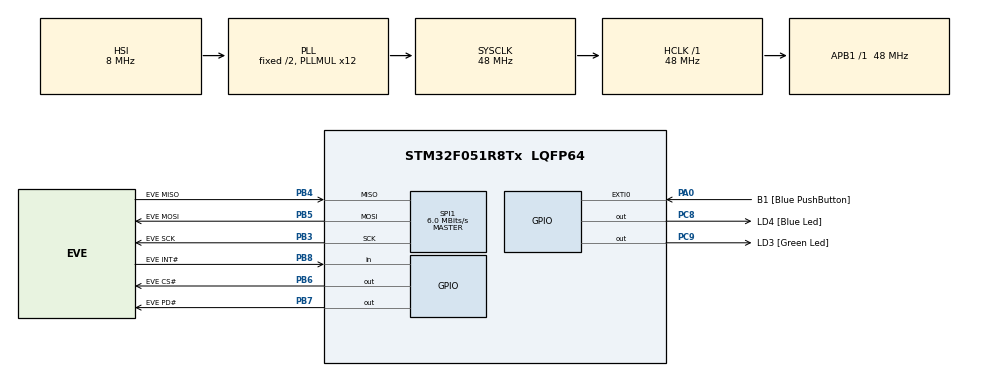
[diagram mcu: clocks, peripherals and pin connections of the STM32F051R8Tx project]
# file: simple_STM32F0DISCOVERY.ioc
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Mcu.Family=STM32F0
Mcu.Name=STM32F051R8Tx
Mcu.Package=LQFP64
PA0.GPIO_Label=B1 [Blue PushButton]
PA0.GPIO_ModeDefaultEXTI=GPIO_MODE_EVT_RISING
PA0.Signal=GPXTI0
PA13.GPIO_Label=SWDIO
PA13.Mode=Serial_Wire
PA13.Signal=SYS_SWDIO
PA14.GPIO_Label=SWCLK
PA14.Mode=Serial_Wire
PA14.Signal=SYS_SWCLK
PB3.GPIO_Label=EVE SCK
PB3.Mode=Full_Duplex_Master
PB3.Signal=SPI1_SCK
PB4.GPIO_Label=EVE MISO
PB4.Mode=Full_Duplex_Master
PB4.Signal=SPI1_MISO
PB5.GPIO_Label=EVE MOSI
PB5.Mode=Full_Duplex_Master
PB5.Signal=SPI1_MOSI
PB6.GPIO_Label=EVE CS\#
PB6.Signal=GPIO_Output
PB7.GPIO_Label=EVE PD\#
PB7.Signal=GPIO_Output
PB8.GPIO_Label=EVE INT\#
PB8.Signal=GPIO_Input
PC8.GPIO_Label=LD4 [Blue Led]
PC8.Signal=GPIO_Output
PC9.GPIO_Label=LD3 [Green Led]
PC9.Signal=GPIO_Output
ProjectManager.HeapSize=0x200
ProjectManager.StackSize=0x400
ProjectManager.TargetToolchain=STM32CubeIDE
RCC.AHBFreq_Value=48000000
RCC.APB1Freq_Value=48000000
RCC.APB1TimFreq_Value=48000000
RCC.HCLKFreq_Value=48000000
RCC.PLLMUL=RCC_PLL_MUL12
RCC.SYSCLKFreq_VALUE=48000000
RCC.SYSCLKSource=RCC_SYSCLKSOURCE_PLLCLK
SPI1.BaudRatePrescaler=SPI_BAUDRATEPRESCALER_8
SPI1.CalculateBaudRate=6.0 MBits/s
SPI1.DataSize=SPI_DATASIZE_8BIT
SPI1.Direction=SPI_DIRECTION_2LINES
SPI1.Mode=SPI_MODE_MASTER
SPI1.VirtualType=VM_MASTER
board=STM32F0DISCOVERY

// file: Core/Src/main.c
/* USER CODE BEGIN Header */
/**
  ******************************************************************************
  * @file           : main.c
  * @brief          : Main program body
  ******************************************************************************
  * @attention
  *
  * Copyright (c) 2026 STMicroelectronics.
  * All rights reserved.
  *
  * This software is licensed under terms that can be found in the LICENSE file
  * in the root directory of this software component.
  * If no LICENSE file comes with this software, it is provided AS-IS.
  *
  ******************************************************************************
  */
/* USER CODE END Header */
#include "main.h"

/* USER CODE BEGIN Includes */
#include <string.h>
#include <stdint.h> // for Uint8/16/32 and Int8/16/32 data types

/* Include the example interface and associated function prototypes. */
#include <eve_example.h>
/* USER CODE END Includes */

SPI_HandleTypeDef hspi1;

/* USER CODE BEGIN PV */

GPIO_TypeDef *config_gpio;
uint16_t config_pin_pd;
uint16_t config_pin_cs;
uint16_t config_pin_int;

/* USER CODE END PV */

void SystemClock_Config(void);
static void MX_GPIO_Init(void);
static void MX_SPI1_Init(void);

int main(void)
{

  /* MCU Configuration--------------------------------------------------------*/

  /* Reset of all peripherals, Initializes the Flash interface and the Systick. */
  HAL_Init();

  /* Configure the system clock */
  SystemClock_Config();

  /* Initialize all configured peripherals */
  MX_GPIO_Init();
  MX_SPI1_Init();
  /* USER CODE BEGIN 2 */

  /* Start example code */
  eve_example();

  /* USER CODE END 2 */

  /* Infinite loop */
  while (1)
  {

  }
}

void SystemClock_Config(void)
{
  RCC_OscInitTypeDef RCC_OscInitStruct = {0};
  RCC_ClkInitTypeDef RCC_ClkInitStruct = {0};

  /** Initializes the RCC Oscillators according to the specified parameters
  * in the RCC_OscInitTypeDef structure.
  */
  RCC_OscInitStruct.OscillatorType = RCC_OSCILLATORTYPE_HSI;
  RCC_OscInitStruct.HSIState = RCC_HSI_ON;
  RCC_OscInitStruct.HSICalibrationValue = RCC_HSICALIBRATION_DEFAULT;
  RCC_OscInitStruct.PLL.PLLState = RCC_PLL_ON;
  RCC_OscInitStruct.PLL.PLLSource = RCC_PLLSOURCE_HSI;
  RCC_OscInitStruct.PLL.PLLMUL = RCC_PLL_MUL12;
  RCC_OscInitStruct.PLL.PREDIV = RCC_PREDIV_DIV1;
  if (HAL_RCC_OscConfig(&RCC_OscInitStruct) != HAL_OK)
  {
    Error_Handler();
  }

  /** Initializes the CPU, AHB and APB buses clocks
  */
  RCC_ClkInitStruct.ClockType = RCC_CLOCKTYPE_HCLK|RCC_CLOCKTYPE_SYSCLK
                              |RCC_CLOCKTYPE_PCLK1;
  RCC_ClkInitStruct.SYSCLKSource = RCC_SYSCLKSOURCE_PLLCLK;
  RCC_ClkInitStruct.AHBCLKDivider = RCC_SYSCLK_DIV1;
  RCC_ClkInitStruct.APB1CLKDivider = RCC_HCLK_DIV1;

  if (HAL_RCC_ClockConfig(&RCC_ClkInitStruct, FLASH_LATENCY_1) != HAL_OK)
  {
    Error_Handler();
  }
}

static void MX_SPI1_Init(void)
{

  /* SPI1 parameter configuration*/
  hspi1.Instance = SPI1;
  hspi1.Init.Mode = SPI_MODE_MASTER;
  hspi1.Init.Direction = SPI_DIRECTION_2LINES;
  hspi1.Init.DataSize = SPI_DATASIZE_8BIT;
  hspi1.Init.CLKPolarity = SPI_POLARITY_LOW;
  hspi1.Init.CLKPhase = SPI_PHASE_1EDGE;
  hspi1.Init.NSS = SPI_NSS_SOFT;
  hspi1.Init.BaudRatePrescaler = SPI_BAUDRATEPRESCALER_8;
  hspi1.Init.FirstBit = SPI_FIRSTBIT_MSB;
  hspi1.Init.TIMode = SPI_TIMODE_DISABLE;
  hspi1.Init.CRCCalculation = SPI_CRCCALCULATION_DISABLE;
  hspi1.Init.CRCPolynomial = 7;
  hspi1.Init.CRCLength = SPI_CRC_LENGTH_DATASIZE;
  hspi1.Init.NSSPMode = SPI_NSS_PULSE_ENABLE;
  if (HAL_SPI_Init(&hspi1) != HAL_OK)
  {
    Error_Handler();
  }

}

static void MX_GPIO_Init(void)
{
  GPIO_InitTypeDef GPIO_InitStruct = {0};

  /* GPIO Ports Clock Enable */
  __HAL_RCC_GPIOA_CLK_ENABLE();
  __HAL_RCC_GPIOC_CLK_ENABLE();
  __HAL_RCC_GPIOB_CLK_ENABLE();

  /*Configure GPIO pin Output Level */
  HAL_GPIO_WritePin(GPIOC, LD4_Pin|LD3_Pin, GPIO_PIN_RESET);

  /*Configure GPIO pin Output Level */
  HAL_GPIO_WritePin(GPIOB, EVE_CS__Pin|EVE_PD__Pin, GPIO_PIN_RESET);

  /*Configure GPIO pin : B1_Pin */
  GPIO_InitStruct.Pin = B1_Pin;
  GPIO_InitStruct.Mode = GPIO_MODE_EVT_RISING;
  GPIO_InitStruct.Pull = GPIO_NOPULL;
  HAL_GPIO_Init(B1_GPIO_Port, &GPIO_InitStruct);

  /*Configure GPIO pins : LD4_Pin LD3_Pin */
  GPIO_InitStruct.Pin = LD4_Pin|LD3_Pin;
  GPIO_InitStruct.Mode = GPIO_MODE_OUTPUT_PP;
  GPIO_InitStruct.Pull = GPIO_NOPULL;
  GPIO_InitStruct.Speed = GPIO_SPEED_FREQ_LOW;
  HAL_GPIO_Init(GPIOC, &GPIO_InitStruct);

  /*Configure GPIO pins : EVE_CS__Pin EVE_PD__Pin */
  GPIO_InitStruct.Pin = EVE_CS__Pin|EVE_PD__Pin;
  GPIO_InitStruct.Mode = GPIO_MODE_OUTPUT_PP;
  GPIO_InitStruct.Pull = GPIO_NOPULL;
  GPIO_InitStruct.Speed = GPIO_SPEED_FREQ_LOW;
  HAL_GPIO_Init(GPIOB, &GPIO_InitStruct);

  /*Configure GPIO pin : EVE_INT__Pin */
  GPIO_InitStruct.Pin = EVE_INT__Pin;
  GPIO_InitStruct.Mode = GPIO_MODE_INPUT;
  GPIO_InitStruct.Pull = GPIO_NOPULL;
  HAL_GPIO_Init(EVE_INT__GPIO_Port, &GPIO_InitStruct);

  /* USER CODE BEGIN MX_GPIO_Init_2 */

    /* Must match above. If this has been changed by STM32CubeMX then update. */
    /* This is extern from the EVE_MCU_STM32.c file. */
    config_gpio = GPIOB;
    config_pin_cs = EVE_CS__Pin;
    config_pin_pd = EVE_PD__Pin;
    config_pin_int = EVE_INT__Pin;

  /* USER CODE END MX_GPIO_Init_2 */
}

void Error_Handler(void)
{
  __disable_irq();
  while (1)
  {
  }
}
